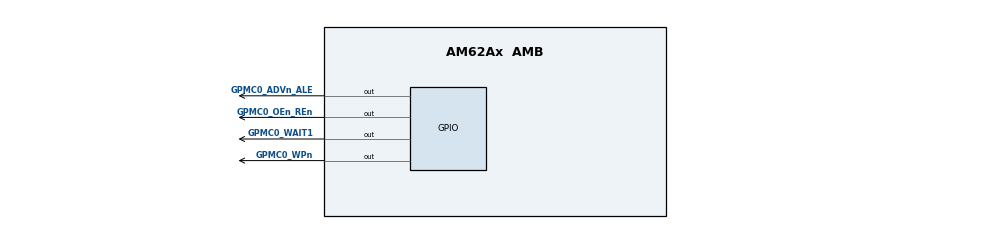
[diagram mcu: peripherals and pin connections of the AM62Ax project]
/**
 * @cliArgs --device "AM62Ax" --package "AMB" --part "Default" --context "c75ss0-0" --product "MCU_PLUS_SDK@07.03.01"
 * @versions {"tool":"1.19.0+3426"}
 */

/**
 * Import the modules used in this configuration.
 */
const eqep       = scripting.addModule("/drivers/eqep/eqep", {}, false);
const eqep1      = eqep.addInstance();
const gpio       = scripting.addModule("/drivers/gpio/gpio", {}, false);
const gpio1      = gpio.addInstance();
const gpio2      = gpio.addInstance();
const gpio3      = gpio.addInstance();
const gpio4      = gpio.addInstance();
const debug_log  = scripting.addModule("/kernel/dpl/debug_log");
const mmu_armv8  = scripting.addModule("/kernel/dpl/mmu_armv8", {}, false);
const mmu_armv81 = mmu_armv8.addInstance();
const mmu_armv82 = mmu_armv8.addInstance();
const mmu_armv83 = mmu_armv8.addInstance();
const mmu_armv84 = mmu_armv8.addInstance();
const mmu_armv85 = mmu_armv8.addInstance();
const mmu_armv86 = mmu_armv8.addInstance();
const mmu_armv87 = mmu_armv8.addInstance();
const mmu_armv88 = mmu_armv8.addInstance();
const mmu_armv89 = mmu_armv8.addInstance();

/**
 * Write custom configuration values to the imported modules.
 */
eqep1.$name          = "CONFIG_EQEP0";
eqep1.EQEP.$assign   = "EQEP2";
eqep1.EQEP.I.$assign = "MCAN0_TX";
eqep1.EQEP.S.$assign = "MCAN0_RX";

gpio1.$name                = "CONFIG_GPIO0";
gpio1.pinDir               = "OUTPUT";
gpio1.GPIO.gpioPin.rx      = false;
gpio1.GPIO.gpioPin.$assign = "GPMC0_WAIT1";

gpio2.$name                = "CONFIG_GPIO1";
gpio2.pinDir               = "OUTPUT";
gpio2.GPIO.gpioPin.rx      = false;
gpio2.GPIO.gpioPin.$assign = "GPMC0_WPn";

gpio3.$name                = "CONFIG_GPIO2";
gpio3.pinDir               = "OUTPUT";
gpio3.GPIO.gpioPin.rx      = false;
gpio3.GPIO.gpioPin.$assign = "GPMC0_ADVn_ALE";

gpio4.$name                = "CONFIG_GPIO3";
gpio4.pinDir               = "OUTPUT";
gpio4.GPIO.gpioPin.rx      = false;
gpio4.GPIO.gpioPin.$assign = "GPMC0_OEn_REn";

debug_log.enableUartLog                   = true;
debug_log.enableCssLog                    = false;
debug_log.uartLog.$name                   = "CONFIG_UART0";
debug_log.uartLog.useMcuDomainPeripherals = true;

mmu_armv81.$name = "CONFIG_MMU_REGION0";
mmu_armv81.size  = 0x20000000;

mmu_armv82.$name = "CONFIG_MMU_REGION1";
mmu_armv82.vAddr = 0x20000000;
mmu_armv82.pAddr = 0x20000000;
mmu_armv82.size  = 0x20000000;

mmu_armv83.$name = "CONFIG_MMU_REGION2";
mmu_armv83.vAddr = 0x40000000;
mmu_armv83.pAddr = 0x40000000;
mmu_armv83.size  = 0x20000000;

mmu_armv84.$name = "CONFIG_MMU_REGION3";
mmu_armv84.vAddr = 0x60000000;
mmu_armv84.pAddr = 0x60000000;
mmu_armv84.size  = 0x10000000;

mmu_armv85.vAddr = 0x7C200000;
mmu_armv85.pAddr = 0x7C200000;
mmu_armv85.$name = "CLEC";
mmu_armv85.size  = 0x100000;

mmu_armv86.$name = "DRU";
mmu_armv86.vAddr = 0x7C400000;
mmu_armv86.pAddr = 0x7C400000;
mmu_armv86.size  = 0x100000;

mmu_armv87.vAddr     = 0x80000000;
mmu_armv87.pAddr     = 0x80000000;
mmu_armv87.size      = 0x20000000;
mmu_armv87.attribute = "MAIR7";
mmu_armv87.$name     = "DDR_0";

mmu_armv88.vAddr     = 0xA0000000;
mmu_armv88.pAddr     = 0xA0000000;
mmu_armv88.size      = 0x20000000;
mmu_armv88.attribute = "MAIR7";
mmu_armv88.$name     = "DDR_1";

mmu_armv89.$name     = "CONFIG_MMU_REGION4";
mmu_armv89.vAddr     = 0xAA000000;
mmu_armv89.pAddr     = 0xAA000000;
mmu_armv89.size      = 0x2000000;
mmu_armv89.attribute = "MAIR4";

/**
 * Pinmux solution for unlocked pins/peripherals. This ensures that minor changes to the automatic solver in a future
 * version of the tool will not impact the pinmux you originally saw.  These lines can be completely deleted in order to
 * re-solve from scratch.
 */
eqep1.EQEP.A.$suggestSolution                   = "I2C0_SCL";
eqep1.EQEP.B.$suggestSolution                   = "I2C0_SDA";
gpio1.GPIO.$suggestSolution                     = "GPIO0";
gpio2.GPIO.$suggestSolution                     = "GPIO0";
gpio3.GPIO.$suggestSolution                     = "GPIO0";
gpio4.GPIO.$suggestSolution                     = "GPIO0";
debug_log.uartLog.MCU_UART.$suggestSolution     = "MCU_USART0";
debug_log.uartLog.MCU_UART.RXD.$suggestSolution = "MCU_UART0_RXD";
debug_log.uartLog.MCU_UART.TXD.$suggestSolution = "MCU_UART0_TXD";
